# STM32G484VET6 register map
File version: 1.0
Registers are 32-bit, access not given, reset 0x0 unless marked. A register's access mark holds for its fields unless they carry their own. Offsets are from the block's base; [hi:lo] are bit positions; {n}, {i} and the like mark numbered series; 'fields as' and 'values as' point back to an identical list.

## ADC1
Base 0x50000000
Same registers: ADC2 0x50000100, ADC3 0x50000400, ADC4 0x50000500, ADC5 0x50000600
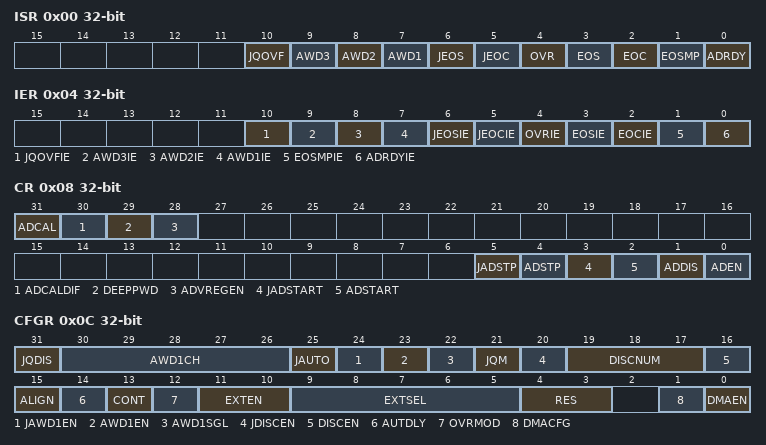
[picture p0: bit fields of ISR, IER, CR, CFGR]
0x00 ISR
  [10] JQOVF, [9] AWD3, [8] AWD2, [7] AWD1, [6] JEOS, [5] JEOC, [4] OVR, [3] EOS, [2] EOC, [1] EOSMP, [0] ADRDY
0x04 IER
  [10] JQOVFIE, [9] AWD3IE, [8] AWD2IE, [7] AWD1IE, [6] JEOSIE, [5] JEOCIE, [4] OVRIE, [3] EOSIE, [2] EOCIE, [1] EOSMPIE, [0] ADRDYIE
0x08 CR
  [31] ADCAL, [30] ADCALDIF, [29] DEEPPWD, [28] ADVREGEN, [5] JADSTP, [4] ADSTP, [3] JADSTART, [2] ADSTART, [1] ADDIS, [0] ADEN
0x0C CFGR
  [31] JQDIS, [30:26] AWD1CH, [25] JAUTO, [24] JAWD1EN, [23] AWD1EN, [22] AWD1SGL, [21] JQM, [20] JDISCEN, [19:17] DISCNUM, [16] DISCEN, [15] ALIGN, [14] AUTDLY, [13] CONT, [12] OVRMOD, [11:10] EXTEN, [9:5] EXTSEL, [4:3] RES, [1] DMACFG, [0] DMAEN
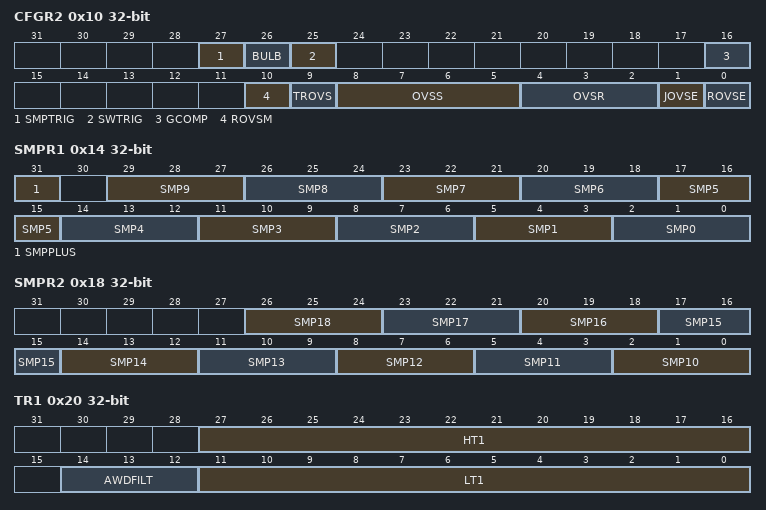
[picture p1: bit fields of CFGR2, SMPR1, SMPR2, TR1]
0x10 CFGR2
  [27] SMPTRIG, [26] BULB, [25] SWTRIG, [16] GCOMP, [10] ROVSM, [9] TROVS, [8:5] OVSS, [4:2] OVSR, [1] JOVSE, [0] ROVSE
0x14 SMPR1
  [31] SMPPLUS, [3n+2:3n] SMP{n} (n=0..9)
0x18 SMPR2
  [3n-28:3n-30] SMP{n} (n=10..18)
0x20 TR1
  [27:16] HT1, [14:12] AWDFILT, [11:0] LT1
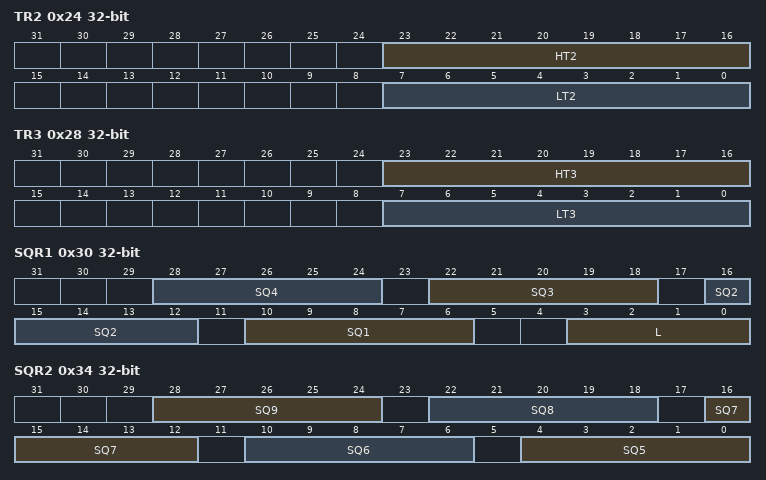
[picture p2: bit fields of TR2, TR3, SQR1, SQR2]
0x24 TR2
  [23:16] HT2, [7:0] LT2
0x28 TR3
  [23:16] HT3, [7:0] LT3
0x30 SQR1
  [6n+4:6n] SQ{n} (n=1..4), [3:0] L
0x34 SQR2
  [6n-26:6n-30] SQ{n} (n=5..9)
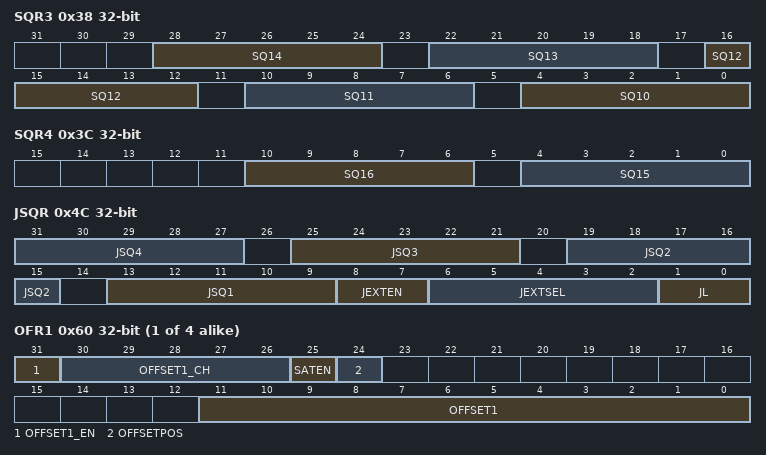
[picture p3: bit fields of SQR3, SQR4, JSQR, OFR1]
0x38 SQR3
  [6n-56:6n-60] SQ{n} (n=10..14)
0x3C SQR4
  [10:6] SQ16, [4:0] SQ15
0x40 DR
  [15:0] RDATA
0x4C JSQR
  [6n+7:6n+3] JSQ{n} (n=1..4), [8:7] JEXTEN, [6:2] JEXTSEL, [1:0] JL
{0x5C+4i} OFR{i} (i=1..4)
  [31] OFFSET{i}_EN, [30:26] OFFSET{i}_CH, [25] SATEN, [24] OFFSETPOS, [11:0] OFFSET{i}
{0x7C+4i} JDR{i} (i=1..4)
  [15:0] JDATA
0xA0 AWD2CR
  [18:0] AWD2CH
0xA4 AWD3CR
  [18:0] AWD3CH
0xB0 DIFSEL
  [18:0] DIFSEL
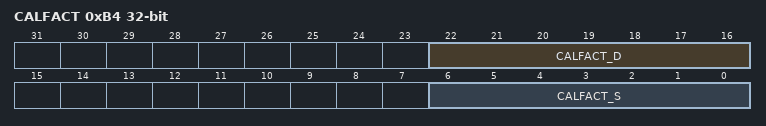
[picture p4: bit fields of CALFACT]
0xB4 CALFACT
  [22:16] CALFACT_D, [6:0] CALFACT_S
0xC0 GCOMP
  [13:0] GCOMPCOEFF

## ADC12_COMMON
Base 0x50000300
Same registers: ADC345_COMMON 0x50000700
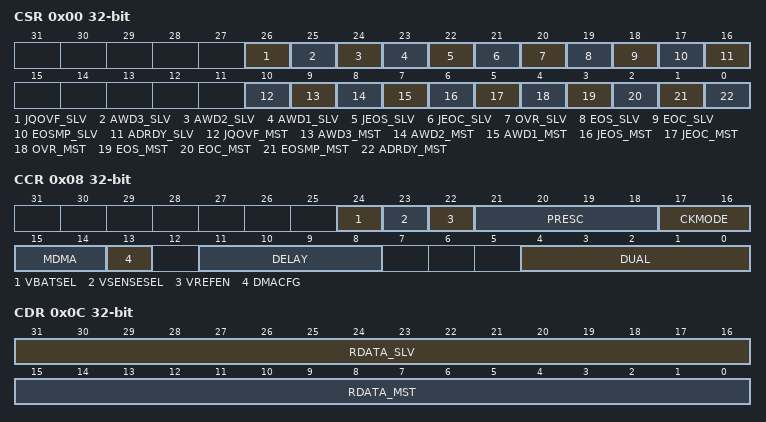
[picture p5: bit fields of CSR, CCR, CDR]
0x00 CSR
  [26] JQOVF_SLV, [25] AWD3_SLV, [24] AWD2_SLV, [23] AWD1_SLV, [22] JEOS_SLV, [21] JEOC_SLV, [20] OVR_SLV, [19] EOS_SLV, [18] EOC_SLV, [17] EOSMP_SLV, [16] ADRDY_SLV, [10] JQOVF_MST, [9] AWD3_MST, [8] AWD2_MST, [7] AWD1_MST, [6] JEOS_MST, [5] JEOC_MST, [4] OVR_MST, [3] EOS_MST, [2] EOC_MST, [1] EOSMP_MST, [0] ADRDY_MST
0x08 CCR
  [24] VBATSEL, [23] VSENSESEL, [22] VREFEN, [21:18] PRESC, [17:16] CKMODE, [15:14] MDMA, [13] DMACFG, [11:8] DELAY, [4:0] DUAL
0x0C CDR
  [31:16] RDATA_SLV, [15:0] RDATA_MST

## DAC
Base 0x50000800
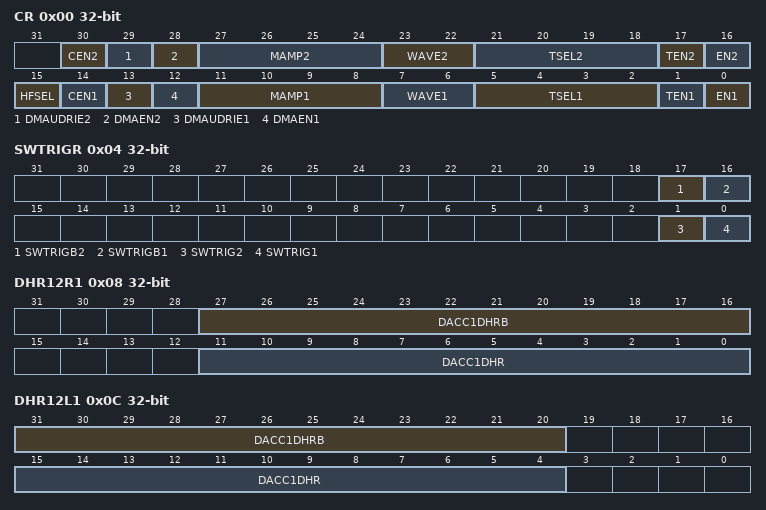
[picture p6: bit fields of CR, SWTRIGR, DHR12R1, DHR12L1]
0x00 CR
  [30] CEN2, [29] DMAUDRIE2, [28] DMAEN2, [27:24] MAMP2, [23:22] WAVE2, [21:18] TSEL2, [17] TEN2, [16] EN2, [15] HFSEL, [14] CEN1, [13] DMAUDRIE1, [12] DMAEN1, [11:8] MAMP1, [7:6] WAVE1, [5:2] TSEL1, [1] TEN1, [0] EN1
0x04 SWTRIGR
  [17] SWTRIGB2, [16] SWTRIGB1, [1] SWTRIG2, [0] SWTRIG1
0x08 DHR12R1
  [27:16] DACC1DHRB, [11:0] DACC1DHR
0x0C DHR12L1
  [31:20] DACC1DHRB, [15:4] DACC1DHR
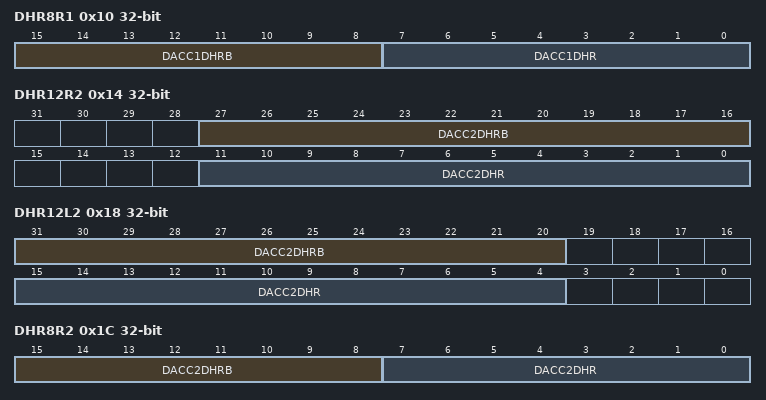
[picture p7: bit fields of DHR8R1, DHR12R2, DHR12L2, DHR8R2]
0x10 DHR8R1
  [15:8] DACC1DHRB, [7:0] DACC1DHR
0x14 DHR12R2
  [27:16] DACC2DHRB, [11:0] DACC2DHR
0x18 DHR12L2
  [31:20] DACC2DHRB, [15:4] DACC2DHR
0x1C DHR8R2
  [15:8] DACC2DHRB, [7:0] DACC2DHR
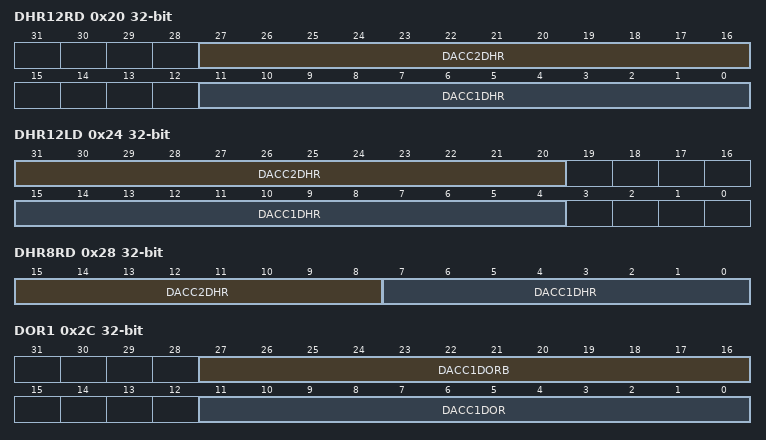
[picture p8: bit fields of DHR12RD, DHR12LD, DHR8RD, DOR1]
0x20 DHR12RD
  [27:16] DACC2DHR, [11:0] DACC1DHR
0x24 DHR12LD
  [31:20] DACC2DHR, [15:4] DACC1DHR
0x28 DHR8RD
  [15:8] DACC2DHR, [7:0] DACC1DHR
0x2C DOR1
  [27:16] DACC1DORB, [11:0] DACC1DOR
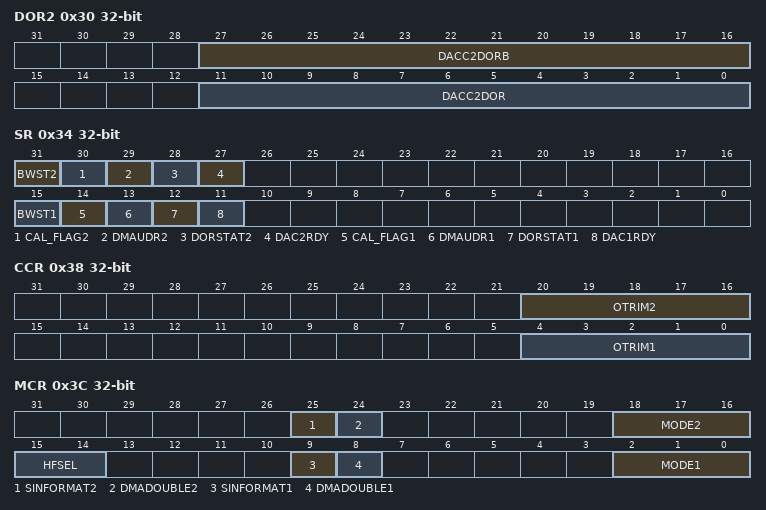
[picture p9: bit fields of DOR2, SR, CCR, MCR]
0x30 DOR2
  [27:16] DACC2DORB, [11:0] DACC2DOR
0x34 SR
  [31] BWST2, [30] CAL_FLAG2, [29] DMAUDR2, [28] DORSTAT2, [27] DAC2RDY, [15] BWST1, [14] CAL_FLAG1, [13] DMAUDR1, [12] DORSTAT1, [11] DAC1RDY
0x38 CCR
  [20:16] OTRIM2, [4:0] OTRIM1
0x3C MCR
  [25] SINFORMAT2, [24] DMADOUBLE2, [18:16] MODE2, [15:14] HFSEL, [9] SINFORMAT1, [8] DMADOUBLE1, [2:0] MODE1
0x40 SHSR1
  [9:0] TSAMPLE1
0x44 SHSR2
  [9:0] TSAMPLE2
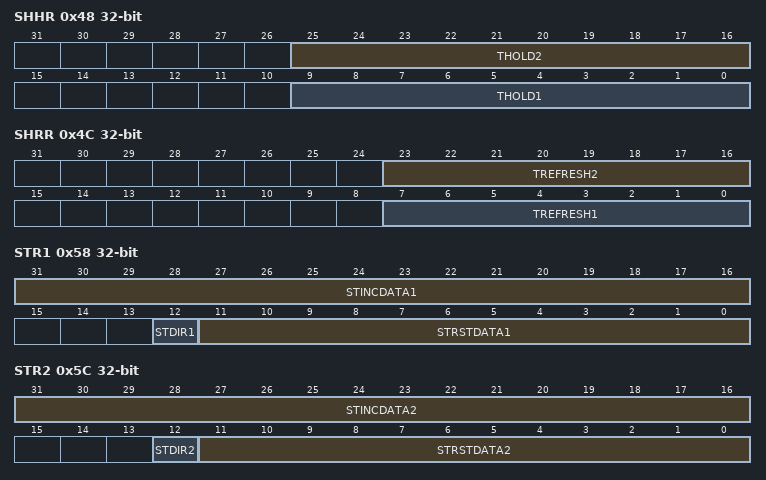
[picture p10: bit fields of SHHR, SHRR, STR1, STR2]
0x48 SHHR
  [25:16] THOLD2, [9:0] THOLD1
0x4C SHRR
  [23:16] TREFRESH2, [7:0] TREFRESH1
0x58 STR1
  [31:16] STINCDATA1, [12] STDIR1, [11:0] STRSTDATA1
0x5C STR2
  [31:16] STINCDATA2, [12] STDIR2, [11:0] STRSTDATA2
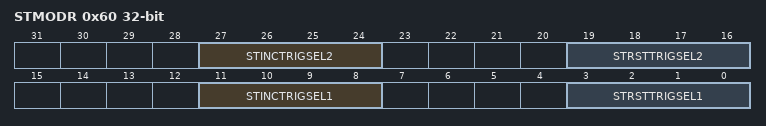
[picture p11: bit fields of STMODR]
0x60 STMODR
  [27:24] STINCTRIGSEL2, [19:16] STRSTTRIGSEL2, [11:8] STINCTRIGSEL1, [3:0] STRSTTRIGSEL1

## DAC1
Base 0x50000800
Registers as DAC; these are added or differ:
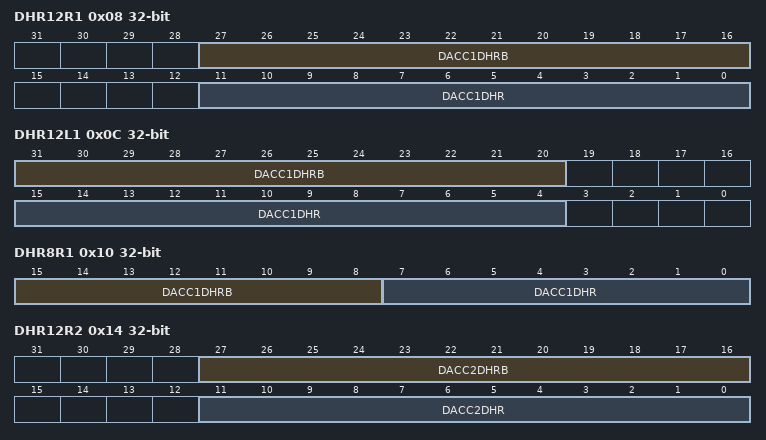
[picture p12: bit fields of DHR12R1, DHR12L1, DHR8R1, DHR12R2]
0x08 DHR12R1
  [27:16] DACC1DHRB, [11:0] DACC1DHR
0x0C DHR12L1
  [31:20] DACC1DHRB, [15:4] DACC1DHR
0x10 DHR8R1
  [15:8] DACC1DHRB, [7:0] DACC1DHR
0x14 DHR12R2
  [27:16] DACC2DHRB, [11:0] DACC2DHR
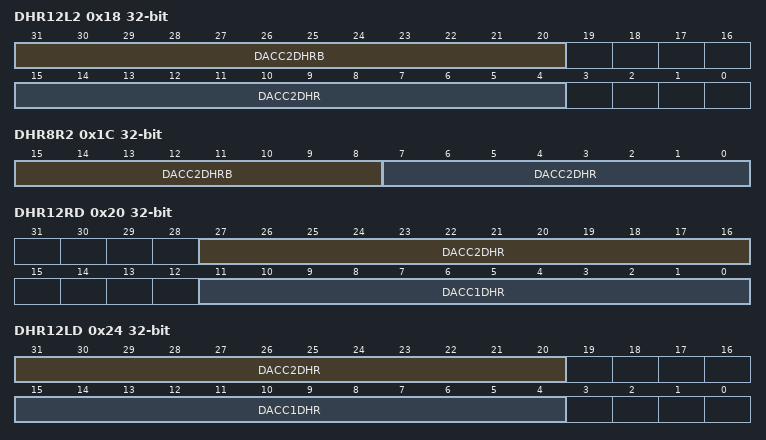
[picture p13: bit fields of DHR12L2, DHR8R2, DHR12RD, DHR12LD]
0x18 DHR12L2
  [31:20] DACC2DHRB, [15:4] DACC2DHR
0x1C DHR8R2
  [15:8] DACC2DHRB, [7:0] DACC2DHR
0x20 DHR12RD
  [27:16] DACC2DHR, [11:0] DACC1DHR
0x24 DHR12LD
  [31:20] DACC2DHR, [15:4] DACC1DHR
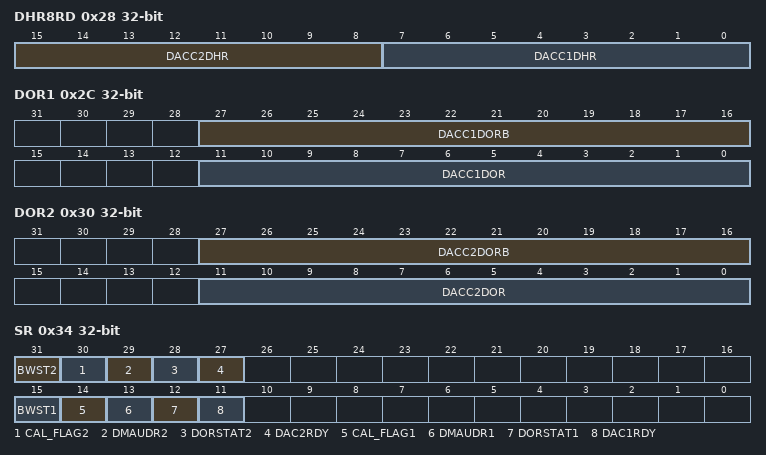
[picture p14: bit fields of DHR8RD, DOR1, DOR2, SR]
0x28 DHR8RD
  [15:8] DACC2DHR, [7:0] DACC1DHR
0x2C DOR1
  [27:16] DACC1DORB, [11:0] DACC1DOR
0x30 DOR2
  [27:16] DACC2DORB, [11:0] DACC2DOR
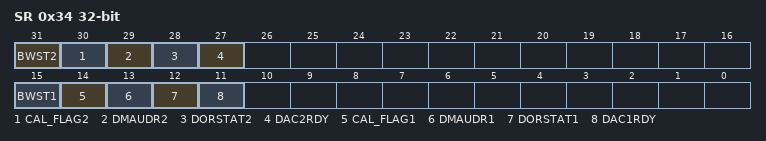
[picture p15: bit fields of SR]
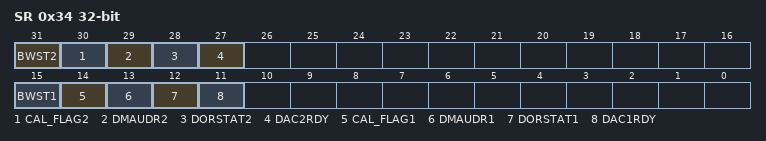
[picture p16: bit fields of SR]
0x34 SR
  [31] BWST2, [30] CAL_FLAG2, [29] DMAUDR2, [28] DORSTAT2, [27] DAC2RDY, [15] BWST1, [14] CAL_FLAG1, [13] DMAUDR1, [12] DORSTAT1, [11] DAC1RDY

## DAC2
Base 0x50000C00
Registers as DAC1; these are added or differ:
0x34 SR
  [31] BWST2, [30] CAL_FLAG2, [29] DMAUDR2, [28] DORSTAT2, [27] DAC2RDY, [15] BWST1, [14] CAL_FLAG1, [13] DMAUDR1, [12] DORSTAT1, [11] DAC1RDY

## DAC3
Base 0x50001000
Same registers: DAC4 0x50001400
Registers as DAC1; these are added or differ:
0x34 SR
  [31] BWST2, [30] CAL_FLAG2, [29] DMAUDR2, [28] DORSTAT2, [27] DAC2RDY, [15] BWST1, [14] CAL_FLAG1, [13] DMAUDR1, [12] DORSTAT1, [11] DAC1RDY

## AES
Base 0x50060000
0x00 CR
  [23:20] NPBLB, [18] KEYSIZE, [14:13] GCMPH, [12] DMAOUTEN, [11] DMAINEN, [10] ERRIE, [9] CCFIE, [8] ERRC, [7] CCFC, [16:5] CHMOD, [4:3] MODE, [2:1] DATATYPE, [0] EN
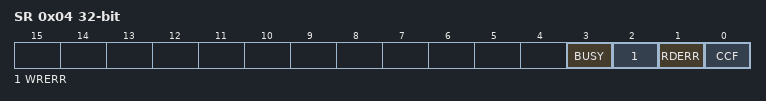
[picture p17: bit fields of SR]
0x04 SR
  [3] BUSY, [2] WRERR, [1] RDERR, [0] CCF
0x08 DINR
0x0C DOUTR
{0x10+4i} KEYR{i} (i=0..3)
{0x20+4i} IVR{i} (i=0..3)
{0x20+4i} KEYR{i} (i=4..7)
{0x40+4i} SUSP{i}R (i=0..7)

## RNG
Base 0x50060800
0x00 CR
  [5] CED, [3] IE, [2] RNGEN
0x04 SR
  [6] SEIS, [5] CEIS, [2] SECS, [1] CECS, [0] DRDY
0x08 DR

## FMC_Bank1_R
Base 0xA0000000
0x00 BTCR.0
0x04 BTCR.1
0x08 BTCR.2
0x0C BTCR.3
0x10 BTCR.4
0x14 BTCR.5
0x18 BTCR.6
0x1C BTCR.7
0x20 PCSCNTR
  [n+15] CNTB{n}EN (n=1..4), [15:0] CSCOUNT

## FMC_Bank3_R
Base 0xA0000080
0x00 PCR
  [19:17] ECCPS, [16:13] TAR, [12:9] TCLR, [6] ECCEN, [5:4] PWID, [3] PTYP, [2] PBKEN, [1] PWAITEN
0x04 SR
  [6] FEMPT, [5] IFEN, [4] ILEN, [3] IREN, [2] IFS, [1] ILS, [0] IRS
0x08 PMEM
  [31:24] MEMHIZ, [23:16] MEMHOLD, [15:8] MEMWAIT, [7:0] MEMSET
0x0C PATT
  [31:24] ATTHIZ, [23:16] ATTHOLD, [15:8] ATTWAIT, [7:0] ATTSET
0x14 ECCR
  [31:0] ECC

## FMC_Bank1E_R
Base 0xA0000104
0x00 BWTR.0
  [31:30] DATAHLD, [29:28] ACCMOD, [19:16] BUSTURN, [15:8] DATAST, [7:4] ADDHLD, [3:0] ADDSET
0x04 BWTR.1
  fields as BWTR.0
0x08 BWTR.2
  fields as BWTR.0
0x0C BWTR.3
  fields as BWTR.0
0x10 BWTR.4
  fields as BWTR.0
0x14 BWTR.5
  fields as BWTR.0
0x18 BWTR.6
  fields as BWTR.0

## QUADSPI
Base 0xA0001000
0x00 CR
  [31:24] PRESCALER, [23] PMM, [22] APMS, [20] TOIE, [19] SMIE, [18] FTIE, [17] TCIE, [16] TEIE, [11:8] FTHRES, [7] FSEL, [6] DFM, [4] SSHIFT, [3] TCEN, [2] DMAEN, [1] ABORT, [0] EN
0x04 DCR
  [20:16] FSIZE, [10:8] CSHT, [0] CKMODE
0x08 SR
  [12:8] FLEVEL, [5] BUSY, [4] TOF, [3] SMF, [2] FTF, [1] TCF, [0] TEF
0x0C FCR
  [4] CTOF, [3] CSMF, [1] CTCF, [0] CTEF
0x10 DLR
  [31:0] DL
0x14 CCR
  [31] DDRM, [30] DHHC, [28] SIOO, [27:26] FMODE, [25:24] DMODE, [22:18] DCYC, [17:16] ABSIZE, [15:14] ABMODE, [13:12] ADSIZE, [11:10] ADMODE, [9:8] IMODE, [7:0] INSTRUCTION
0x18 AR
  [31:0] ADDRESS
0x1C ABR
  [31:0] ALTERNATE
0x20 DR
  [31:0] DATA
0x24 PSMKR
  [31:0] MASK
0x28 PSMAR
  [31:0] MATCH
0x2C PIR
  [15:0] INTERVAL
0x30 LPTR
  [15:0] TIMEOUT

## DBGMCU
Base 0xE0042000
0x00 IDCODE
  [31:16] REV_ID, [11:0] DEV_ID
0x04 CR
  [7:6] TRACE_MODE, [5] TRACE_IOEN, [2] DBG_STANDBY, [1] DBG_STOP, [0] DBG_SLEEP
0x08 APB1FZR1
  [31] DBG_LPTIM1_STOP, [30] DBG_I2C3_STOP, [22] DBG_I2C2_STOP, [21] DBG_I2C1_STOP, [12] DBG_IWDG_STOP, [11] DBG_WWDG_STOP, [10] DBG_RTC_STOP, [n-2] DBG_TIM{n}_STOP (n=2..7)
0x0C APB1FZR2
  [1] DBG_I2C4_STOP
0x10 APB2FZ
  [26] DBG_HRTIM1_STOP, [20] DBG_TIM20_STOP, [18] DBG_TIM17_STOP, [17] DBG_TIM16_STOP, [16] DBG_TIM15_STOP, [13] DBG_TIM8_STOP, [11] DBG_TIM1_STOP
